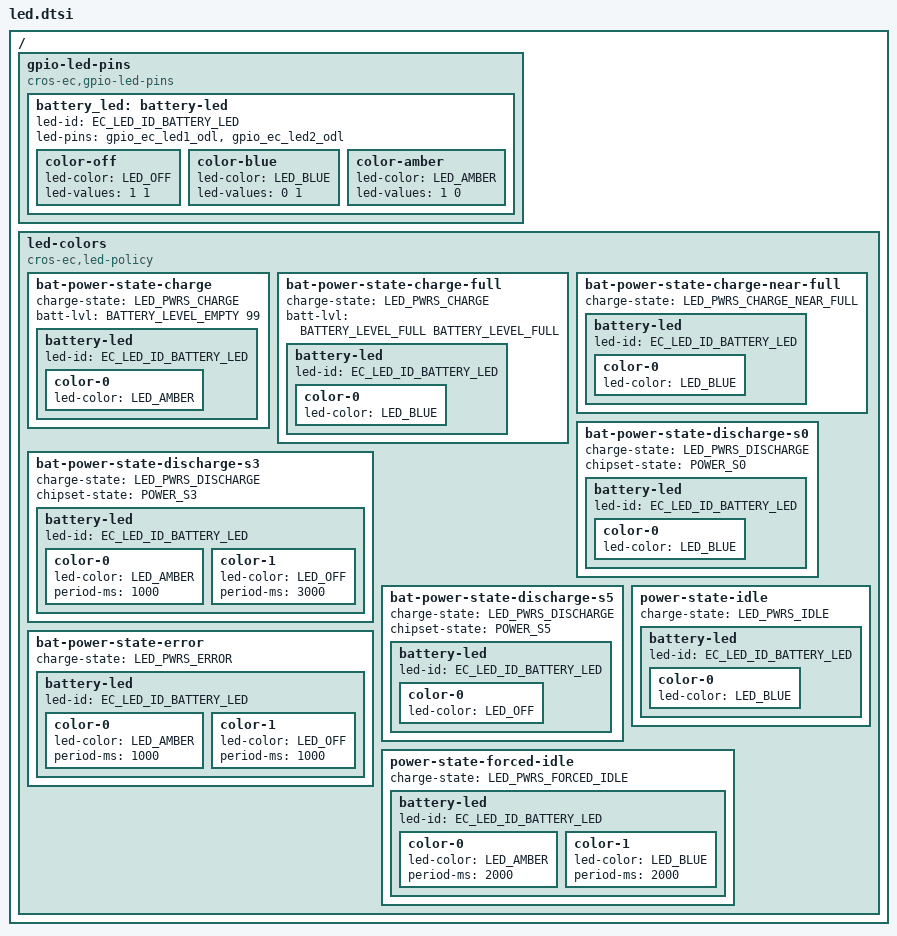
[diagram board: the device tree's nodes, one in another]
/* Copyright 2024 The ChromiumOS Authors
 * Use of this source code is governed by a BSD-style license that can be
 * found in the LICENSE file.
 */
#include <dt-bindings/battery.h>

/ {
	gpio-led-pins {
		compatible = "cros-ec,gpio-led-pins";

		battery_led: battery-led {
			led-id = "EC_LED_ID_BATTERY_LED";
			led-pins = <&gpio_ec_led1_odl &gpio_ec_led2_odl>;

			color-off {
				led-color = "LED_OFF";
				led-values = <1 1>;
			};

			color-blue {
				led-color = "LED_BLUE";
				led-values = <0 1>;
			};

			color-amber {
				led-color = "LED_AMBER";
				led-values = <1 0>;
			};
		};
	};

	led-colors {
		compatible = "cros-ec,led-policy";

		/* Hylia LED bat charge */
		bat-power-state-charge {
			charge-state = "LED_PWRS_CHARGE";
			/* Battery display percent range (>= Empty, <= 99%) */
			batt-lvl = <BATTERY_LEVEL_EMPTY 99>;

			battery-led {
				led-id = "EC_LED_ID_BATTERY_LED";

				color-0 {
					led-color = "LED_AMBER";
				};
			};
		};

		/* Hylia LED bat charge, full batt-lvl */
		bat-power-state-charge-full {
			charge-state = "LED_PWRS_CHARGE";
			/* Battery display percent range (100%) */
			batt-lvl = <BATTERY_LEVEL_FULL BATTERY_LEVEL_FULL>;

			battery-led {
				led-id = "EC_LED_ID_BATTERY_LED";

				color-0 {
					led-color = "LED_BLUE";
				};
			};
		};

		/* Hylia LED bat charge near full */
		bat-power-state-charge-near-full {
			charge-state = "LED_PWRS_CHARGE_NEAR_FULL";

			battery-led {
				led-id = "EC_LED_ID_BATTERY_LED";

				color-0 {
					led-color = "LED_BLUE";
				};
			};
		};

		/* Hylia LED bat discharge */
		bat-power-state-discharge-s0 {
			charge-state = "LED_PWRS_DISCHARGE";
			chipset-state = "POWER_S0";

			battery-led {
				led-id = "EC_LED_ID_BATTERY_LED";

				color-0 {
					led-color = "LED_BLUE";
				};
			};
		};

		bat-power-state-discharge-s3 {
			charge-state = "LED_PWRS_DISCHARGE";
			chipset-state = "POWER_S3";

			battery-led {
				led-id = "EC_LED_ID_BATTERY_LED";

				color-0 {
					led-color = "LED_AMBER";
					period-ms = <1000>;
				};
				color-1 {
					led-color = "LED_OFF";
					period-ms = <3000>;
				};
			};
		};

		bat-power-state-discharge-s5 {
			charge-state = "LED_PWRS_DISCHARGE";
			chipset-state = "POWER_S5";

			battery-led {
				led-id = "EC_LED_ID_BATTERY_LED";

				color-0 {
					led-color = "LED_OFF";
				};
			};
		};

		/* Hylia LED bat error */
		bat-power-state-error {
			charge-state = "LED_PWRS_ERROR";

			battery-led {
				led-id = "EC_LED_ID_BATTERY_LED";

				color-0 {
					led-color = "LED_AMBER";
					period-ms = <1000>;
				};
				color-1 {
					led-color = "LED_OFF";
					period-ms = <1000>;
				};
			};
		};

		/* Hylia LED power idle */
		power-state-idle {
			charge-state = "LED_PWRS_IDLE";

			battery-led {
				led-id = "EC_LED_ID_BATTERY_LED";

				color-0 {
					led-color = "LED_BLUE";
				};
			};
		};

		/* Hylia LED power forced idle */
		power-state-forced-idle {
			charge-state = "LED_PWRS_FORCED_IDLE";

			battery-led {
				led-id = "EC_LED_ID_BATTERY_LED";

				color-0 {
					led-color = "LED_AMBER";
					period-ms = <2000>;
				};
				color-1 {
					led-color = "LED_BLUE";
					period-ms = <2000>;
				};
			};
		};
	};
};
